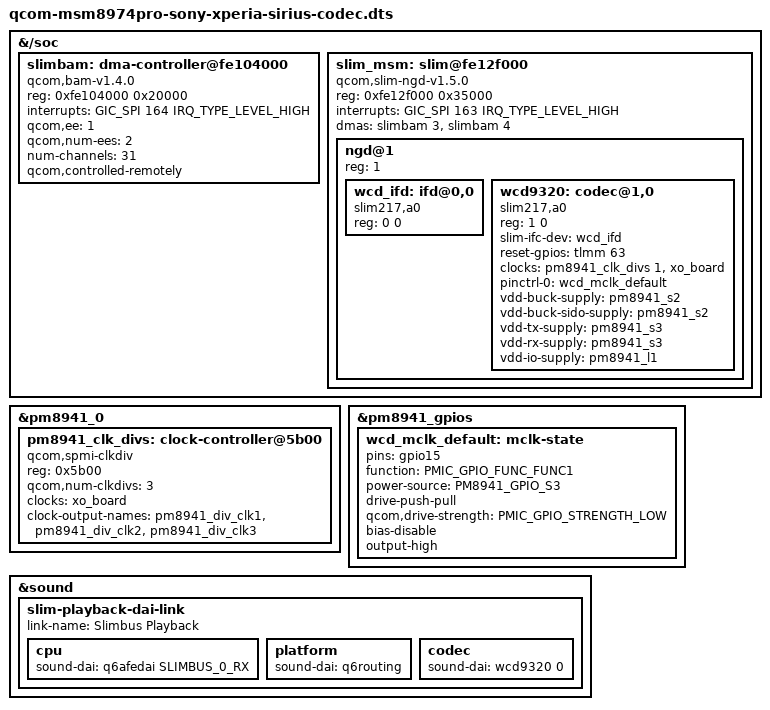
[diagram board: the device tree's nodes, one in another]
// SPDX-License-Identifier: GPL-2.0
/*
 * Sony Xperia Z2 (sirius): WCD9320 (Taiko) codec on SLIMbus.
 *
 * The headphone jack and all three microphones are on this codec; the
 * earpiece is the top TFA9890 on MI2S and does not need it. The codec hangs
 * off the LPASS SLIMbus NGD controller (fe12f000), whose data moves through
 * the SLIMbus BAM (fe104000, run by the ADSP: "controlled-remotely").
 * Mainline's qcom-ngd-ctrl drives it with the msm8996 compatible, and the
 * ADSP firmware exposes the SLIMbus QMI service it needs.
 *
 * This describes the driver in drivers-wip/wcd9320 (z3ntu's 5.11 codec
 * forward-ported to 6.16): a plain SLIMbus device with no platform child,
 * taking its interface device by phandle. Supplies, the reset line and the
 * 9.6 MHz master clock are Sony's downstream values.
 *
 * The master clock is the part that is easy to get wrong. The codec needs
 * 9.6 MHz on its MCLK pin. That clock is made inside the PM8941 by dividing
 * the 19.2 MHz crystal, and it leaves the PMIC on PMIC GPIO 15, whose
 * alternate function 1 is the divider output. Both halves have to be set up:
 * the divider (clock-controller@5b00, driven by drivers/clk/pmic-clkdiv) and
 * the pin (wcd_mclk_default below). The RPM's div_clk1 is not a substitute:
 * mainline models it as an XO buffer fixed at 19.2 MHz, so it cannot be set
 * to 9.6, and it does not touch the pin at all. With the pin left as a plain
 * input the codec still answers on SLIMbus and every register write lands,
 * but the DAC has no clock and the headphones stay silent.
 *
 * Builds on the FM variant so one image carries both.
 */
#include "qcom-msm8974pro-sony-xperia-sirius-fmaudio.dts"
#include <dt-bindings/pinctrl/qcom,pmic-gpio.h>

&{/soc} {
	slimbam: dma-controller@fe104000 {
		compatible = "qcom,bam-v1.4.0";
		reg = <0xfe104000 0x20000>;
		interrupts = <GIC_SPI 164 IRQ_TYPE_LEVEL_HIGH>;
		#dma-cells = <1>;
		qcom,ee = <1>;
		qcom,num-ees = <2>;
		num-channels = <31>;
		qcom,controlled-remotely;
	};

	slim_msm: slim@fe12f000 {
		compatible = "qcom,slim-ngd-v1.5.0";
		reg = <0xfe12f000 0x35000>;
		interrupts = <GIC_SPI 163 IRQ_TYPE_LEVEL_HIGH>;
		dmas = <&slimbam 3>, <&slimbam 4>;
		dma-names = "rx", "tx";
		#address-cells = <1>;
		#size-cells = <0>;

		ngd@1 {
			reg = <1>;
			#address-cells = <2>;
			#size-cells = <0>;

			/* interface device: manufacturer 0x217, product 0xa0 */
			wcd_ifd: ifd@0,0 {
				compatible = "slim217,a0";
				reg = <0 0>;
			};

			wcd9320: codec@1,0 {
				compatible = "slim217,a0";
				reg = <1 0>;

				slim-ifc-dev = <&wcd_ifd>;

				reset-gpios = <&tlmm 63 GPIO_ACTIVE_HIGH>;

				clocks = <&pm8941_clk_divs 1>, <&xo_board>;
				clock-names = "mclk", "slimbus";

				pinctrl-names = "default";
				pinctrl-0 = <&wcd_mclk_default>;

				vdd-buck-supply = <&pm8941_s2>;
				vdd-buck-sido-supply = <&pm8941_s2>;
				vdd-tx-supply = <&pm8941_s3>;
				vdd-rx-supply = <&pm8941_s3>;
				vdd-io-supply = <&pm8941_l1>;

				#sound-dai-cells = <1>;
			};
		};
	};
};

/*
 * The PM8941 clock dividers. Divider 1 feeds the codec. The names are spelled
 * out because the RPM clock controller on this SoC has already registered
 * "div_clk1" and "div_clk2"; without distinct names this controller fails to
 * probe with -EEXIST. See publish/drivers/clk/pmic-clkdiv/.
 */
&pm8941_0 {
	pm8941_clk_divs: clock-controller@5b00 {
		compatible = "qcom,spmi-clkdiv";
		reg = <0x5b00>;
		#clock-cells = <1>;
		qcom,num-clkdivs = <3>;
		clocks = <&xo_board>;
		clock-names = "xo";
		clock-output-names = "pm8941_div_clk1", "pm8941_div_clk2",
				     "pm8941_div_clk3";
	};
};

/*
 * PMIC GPIO 15 carries divider 1 out to the codec's MCLK pin. Sony's
 * downstream tree sets mode 1 (digital output), src-sel 2 (function 1),
 * vin-sel 2 (S3), no pull and low drive strength; this is that, in mainline
 * spelling.
 */
&pm8941_gpios {
	wcd_mclk_default: mclk-state {
		pins = "gpio15";
		function = PMIC_GPIO_FUNC_FUNC1;
		power-source = <PM8941_GPIO_S3>;
		drive-push-pull;
		qcom,drive-strength = <PMIC_GPIO_STRENGTH_LOW>;
		bias-disable;
		output-high;
	};
};

&sound {
	slim-playback-dai-link {
		link-name = "Slimbus Playback";

		cpu {
			sound-dai = <&q6afedai SLIMBUS_0_RX>;
		};

		platform {
			sound-dai = <&q6routing>;
		};

		codec {
			/* DAI 0 is wcd9320_rx1, stream "AIF1 Playback" */
			sound-dai = <&wcd9320 0>;
		};
	};
};
